# STM32L151xDx register map
File version: 1.0
Registers are 32-bit, read-write, reset 0x0 unless marked. A register's access mark holds for its fields unless they carry their own. Offsets are from the block's base; [hi:lo] are bit positions; lines under a group give offsets from that group.

## COMP — Comparator
Base 0x40007C00
Same registers: COMP1 0x40007C00 (alternate view of COMP), COMP2 0x40007C01
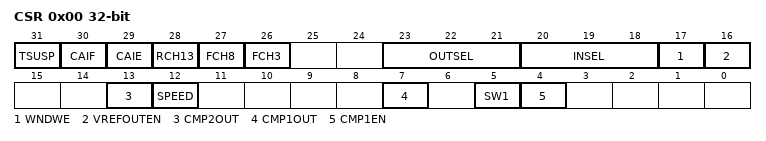
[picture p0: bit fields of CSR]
0x00 CSR — COMP control and status register
  [31] TSUSP — Bit 31
  [30] CAIF — Bit 30
  [29] CAIE — Bit 29
  [28] RCH13 — Bit 28
  [27] FCH8 — Bit 27
  [26] FCH3 — Bit 26
  [23:21] OUTSEL — Comparator 2 output redirection
    7=NONE (COMP output is not connected to other peripherals (except GPIO and EXTI that are always connected to COMP output) (specific to COMP instance: COMP2)); 0=TIM2_IC4 (COMP output connected to TIM2 input capture 4 (specific to COMP instance: COMP2)); 1=TIM2_OCREFCLR (COMP output connected to TIM2 OCREF clear (specific to COMP instance: COMP2)); 2=TIM3_IC4 (COMP output connected to TIM3 input capture 4 (specific to COMP instance: COMP2)); 3=TIM3_OCREFCLR (COMP output connected to TIM3 OCREF clear (specific to COMP instance: COMP2)); 4=TIM4_IC4 (COMP output connected to TIM4 input capture 4 (specific to COMP instance: COMP2)); 5=TIM4_OCREFCLR (COMP output connected to TIM4 OCREF clear (specific to COMP instance: COMP2)); 6=TIM10_IC1 (COMP output connected to TIM10 input capture 1 (specific to COMP instance: COMP2))
  [20:18] INSEL — Comparator 2 input minus selection
    5=MINUS_1_4VREFINT (Comparator input minus connected to 1/4 VrefInt (specific to COMP instance: COMP2)); 4=MINUS_1_2VREFINT (Comparator input minus connected to 1/2 VrefInt (specific to COMP instance: COMP2)); 3=MINUS_3_4VREFINT (Comparator input minus connected to 3/4 VrefInt (specific to COMP instance: COMP2)); 2=VREFINT (Comparator input minus connected to VrefInt); 6=DAC1_CH1 (Comparator input minus connected to DAC1 channel 1 (DAC_OUT1) (specific to COMP instance: COMP2)); 7=DAC1_CH2 (Comparator input minus connected to DAC1 channel 2 (DAC_OUT2) (specific to COMP instance: COMP2)); 1=IO1 (Comparator input minus connected to IO1 (pin PB3 for COMP2) (specific to COMP instance: COMP2))
  [17] WNDWE — Pair of comparators window mode. Bit intended to be used with COMP common instance (COMP_Common_TypeDef)
    0=DISABLE (Window mode disable: Comparators 1 and 2 are independent); 1=COMP2_INPUT_PLUS_COMMON (Window mode enable: Comparators instances pair COMP1 and COMP2 have their input plus connected together. The common input is COMP2 input plus (COMP1 input plus is no more accessible, either from GPIO and from ADC channel VCOMP).)
  [16] VREFOUTEN — VrefInt output enable on GPIO group 3
  [13] CMP2OUT — Comparator 2 output level
  [12] SPEED — Comparator 2 power mode
    1=MEDIUMSPEED (COMP power mode to fast speed (specific to COMP instance: COMP2)); 0=ULTRALOWPOWER (COMP power mode to low speed (specific to COMP instance: COMP2))
  [7] CMP1OUT — Comparator 1 output level
  [5] SW1 — SW1 analog switch enable
  [4] CMP1EN — Comparator 1 enable

## COMP12_COMMON
Base 0x40007C00; alternate view of COMP
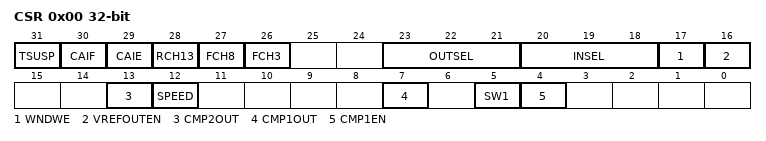
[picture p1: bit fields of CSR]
0x00 CSR — COMP control and status register, used for bits common to several COMP instances
  [31] TSUSP — Bit 31
  [30] CAIF — Bit 30
  [29] CAIE — Bit 29
  [28] RCH13 — Bit 28
  [27] FCH8 — Bit 27
  [26] FCH3 — Bit 26
  [23:21] OUTSEL — Comparator 2 output redirection
    7=NONE (COMP output is not connected to other peripherals (except GPIO and EXTI that are always connected to COMP output) (specific to COMP instance: COMP2)); 0=TIM2_IC4 (COMP output connected to TIM2 input capture 4 (specific to COMP instance: COMP2)); 1=TIM2_OCREFCLR (COMP output connected to TIM2 OCREF clear (specific to COMP instance: COMP2)); 2=TIM3_IC4 (COMP output connected to TIM3 input capture 4 (specific to COMP instance: COMP2)); 3=TIM3_OCREFCLR (COMP output connected to TIM3 OCREF clear (specific to COMP instance: COMP2)); 4=TIM4_IC4 (COMP output connected to TIM4 input capture 4 (specific to COMP instance: COMP2)); 5=TIM4_OCREFCLR (COMP output connected to TIM4 OCREF clear (specific to COMP instance: COMP2)); 6=TIM10_IC1 (COMP output connected to TIM10 input capture 1 (specific to COMP instance: COMP2))
  [20:18] INSEL — Comparator 2 input minus selection
    5=MINUS_1_4VREFINT (Comparator input minus connected to 1/4 VrefInt (specific to COMP instance: COMP2)); 4=MINUS_1_2VREFINT (Comparator input minus connected to 1/2 VrefInt (specific to COMP instance: COMP2)); 3=MINUS_3_4VREFINT (Comparator input minus connected to 3/4 VrefInt (specific to COMP instance: COMP2)); 2=VREFINT (Comparator input minus connected to VrefInt); 6=DAC1_CH1 (Comparator input minus connected to DAC1 channel 1 (DAC_OUT1) (specific to COMP instance: COMP2)); 7=DAC1_CH2 (Comparator input minus connected to DAC1 channel 2 (DAC_OUT2) (specific to COMP instance: COMP2)); 1=IO1 (Comparator input minus connected to IO1 (pin PB3 for COMP2) (specific to COMP instance: COMP2))
  [17] WNDWE — Pair of comparators window mode. Bit intended to be used with COMP common instance (COMP_Common_TypeDef)
    0=DISABLE (Window mode disable: Comparators 1 and 2 are independent); 1=COMP2_INPUT_PLUS_COMMON (Window mode enable: Comparators instances pair COMP1 and COMP2 have their input plus connected together. The common input is COMP2 input plus (COMP1 input plus is no more accessible, either from GPIO and from ADC channel VCOMP).)
  [16] VREFOUTEN — VrefInt output enable on GPIO group 3
  [13] CMP2OUT — Comparator 2 output level
  [12] SPEED — Comparator 2 power mode
    1=MEDIUMSPEED (COMP power mode to fast speed (specific to COMP instance: COMP2)); 0=ULTRALOWPOWER (COMP power mode to low speed (specific to COMP instance: COMP2))
  [7] CMP1OUT — Comparator 1 output level
  [5] SW1 — SW1 analog switch enable
  [4] CMP1EN — Comparator 1 enable
